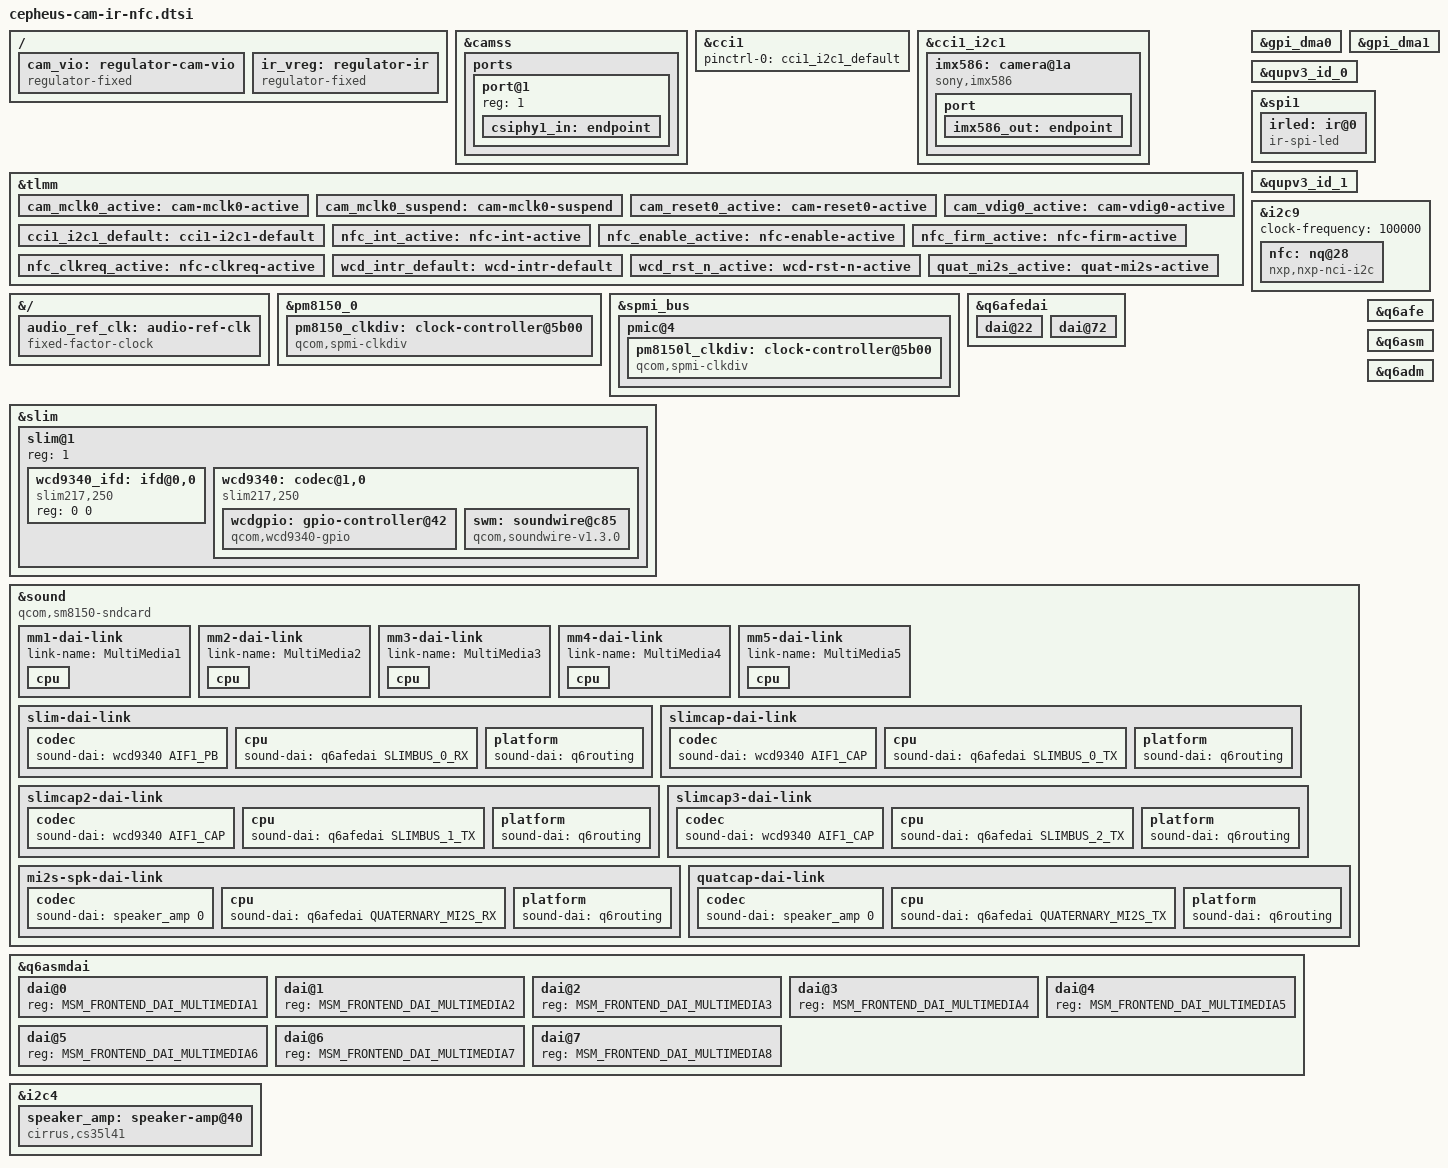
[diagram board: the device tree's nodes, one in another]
// SPDX-License-Identifier: GPL-2.0
#include <dt-bindings/sound/qcom,q6afe.h>
#include <dt-bindings/sound/qcom,q6asm.h>
#include <dt-bindings/sound/qcom,wcd934x.h>
/*
 * Xiaomi Mi 9 (cepheus) 鈥旓拷?鐩告満 / 绾㈠ / NFC 鐨勬澘绾цˉ锟? *
 * 锟?scripts/apply-dts5.sh 杩藉姞锟?sm8150-xiaomi-cepheus.dts 鏈熬锟? * 杩欐牱 07-rebuild-all 涔嬬被鐨勫畬鏁撮噸寤轰笉浼氭妸瀹冨啿鎺夛拷? *
 * 鐩告満閮ㄥ垎鐩墠鐘舵€侊細SoC 渚у叏閮ㄦ墦閫氾紙鏃堕挓/GDSC/CCI/camss锛夛紝
 * 浣嗘ā缁勬湰韬笉涓婄數锛岃锟?docs/camera-port.md 搂15锟? */

/ {
	/* 鐩告満 VIO锟?.8V锛孏PIO132 浣胯兘锛堝師锟?camera_viodd_ldo锟?*/
	cam_vio: regulator-cam-vio {
		compatible = "regulator-fixed";
		regulator-name = "cam_vio";
		regulator-min-microvolt = <1800000>;
		regulator-max-microvolt = <1800000>;
		regulator-enable-ramp-delay = <135>;
		enable-active-high;
		gpio = <&tlmm 132 GPIO_ACTIVE_HIGH>;
		regulator-always-on;
	};

	/* 绾㈠鍙戝皠绠＄殑渚涚數锛坕r-spi 椹卞姩瑕佹眰鍚嶄负 irda_regulator 鐨勭數婧愶級 */
	ir_vreg: regulator-ir {
		compatible = "regulator-fixed";
		regulator-name = "ir_vreg";
		regulator-min-microvolt = <3300000>;
		regulator-max-microvolt = <3300000>;
		regulator-always-on;
	};
};

/* ================= 鐩告満 ================= */

&camss {
	status = "okay";

	ports {
		#address-cells = <1>;
		#size-cells = <0>;

		port@1 {
			reg = <1>;

			csiphy1_in: endpoint {
				remote-endpoint = <&imx586_out>;
				bus-type = <4>;
				data-lanes = <1 2 3 4>;
				link-frequencies = /bits/ 64 <400000000>;
			};
		};
	};
};

&cci1 {
	status = "okay";
	pinctrl-names = "default";
	pinctrl-0 = <&cci1_i2c1_default>;
};

&cci1_i2c1 {
	status = "okay";

	imx586: camera@1a {
		compatible = "sony,imx586";
		reg = <0x1a>;

		reset-gpios = <&tlmm 30 GPIO_ACTIVE_HIGH>;
		pwdn-gpios = <&tlmm 59 GPIO_ACTIVE_HIGH>;

		clocks = <&camcc CAM_CC_MCLK1_CLK>;
		clock-names = "xvclk";

		pinctrl-names = "default", "suspend";
		pinctrl-0 = <&cam_mclk0_active &cam_reset0_active &cam_vdig0_active>;
		pinctrl-1 = <&cam_mclk0_suspend>;

		/* IMX586锛欰VDD 2.8V銆丏OVDD 1.8V銆丏VDD 1.1锟?.9V
		 * 鍘熷巶 DT 鍛藉悕鏄弽鐨勶紙cam_vdig 2.856V 鎵嶆槸 AVDD锟?		 */
		avdd-supply = <&vreg_l17a_3p0>;
		dovdd-supply = <&cam_vio>;
		dvdd-supply = <&vreg_s5a_1p9>;

		port {
			imx586_out: endpoint {
				remote-endpoint = <&csiphy1_in>;
				bus-type = <4>;
				data-lanes = <1 2 3 4>;
				link-frequencies = /bits/ 64 <400000000>;
			};
		};
	};
};

&tlmm {
	cam_mclk0_active: cam-mclk0-active {
		pins = "gpio14";
		function = "cam_mclk";
		drive-strength = <2>;
		bias-disable;
	};

	cam_mclk0_suspend: cam-mclk0-suspend {
		pins = "gpio14";
		function = "cam_mclk";
		drive-strength = <2>;
		bias-pull-down;
	};

	cam_reset0_active: cam-reset0-active {
		pins = "gpio30";
		function = "gpio";
		drive-strength = <2>;
		bias-disable;
	};

	cam_vdig0_active: cam-vdig0-active {
		pins = "gpio59";
		function = "gpio";
		drive-strength = <2>;
		bias-disable;
	};

	cci1_i2c1_default: cci1-i2c1-default {
		pins = "gpio31", "gpio32", "gpio33", "gpio34";
		function = "cci_i2c";
		drive-strength = <2>;
		bias-disable;
	};
};

/* ================= 绾㈠锛圫PI1 / QUP S1, gpio114-117锟?================= */

/* QUP 锟?GPI DMA锛坓eni-i2c/spi 闇€瑕侊級 */
&gpi_dma0 {
	status = "okay";
};

&gpi_dma1 {
	status = "okay";
};

/* IR 锟?qupv3_id_0锛坓eniqup@8c0000锛変笅锟?spi1 */
&qupv3_id_0 {
	status = "okay";
};

&spi1 {
	status = "okay";

	irled: ir@0 {
		compatible = "ir-spi-led";
		reg = <0>;
		spi-max-frequency = <19200000>;
		irda_regulator-supply = <&ir_vreg>;
	};
};

/* ================= NFC锛圢XP NQ, i2c9, 鍦板潃 0x28锟?================= */

&tlmm {
	nfc_int_active: nfc-int-active {
		pins = "gpio47";
		function = "gpio";
		drive-strength = <2>;
		bias-pull-up;
	};

	nfc_enable_active: nfc-enable-active {
		pins = "gpio103";
		function = "gpio";
		drive-strength = <2>;
		bias-disable;
	};

	nfc_firm_active: nfc-firm-active {
		pins = "gpio48";
		function = "gpio";
		drive-strength = <2>;
		bias-disable;
	};

	/* 原锟斤拷锟斤拷 NFC 锟斤拷 CLKREQ 锟脚ｏ拷GPIO113锟斤拷锟斤拷纱锟斤拷锟斤拷锟斤拷锟斤拷锟斤拷耄?	 * 锟斤拷锟斤拷幕锟斤拷锟斤拷锟斤拷锟斤拷锟秸ｏ拷芯片锟矫诧拷锟斤拷锟轿匡拷时锟接ｏ拷I2C 锟斤拷直锟斤拷锟斤拷应锟斤拷-121锟斤拷锟斤拷
	 */
	nfc_clkreq_active: nfc-clkreq-active {
		pins = "gpio113";
		function = "gpio";
		drive-strength = <2>;
		bias-pull-up;
	};};

/* NFC 锟?qupv3_id_1锛坓eniqup@ac0000锛変笅锟?i2c9 */
&qupv3_id_1 {
	status = "okay";
};

/* RPMH 鐨?LN_BB_CLK2 鍥哄畾 19.2MHz锛岃€?WCD9340 闇€瑕?9.6MHz銆? * 鍘熷巶鐢?qcom,audio-ref-clk 椹卞姩浜屽垎棰戯紝涓荤嚎娌¤繖涓┍鍔紝
 * 鎴戜滑涓€鐩存妸 19.2MHz 鐩存帴缁?codec銆侀┍鍔ㄥ嵈鎸?9.6MHz 绠楀垎棰戯紝
 * 鏃堕挓宸?2 鍊?鈥斺€?杩欐槸 ADC/DEC 鏃犳硶宸ヤ綔鐨勭洿鎺ュ師鍥犮€? * 鐢ㄦ爣鍑?fixed-factor-clock 瀹炵幇浜屽垎棰戙€? */
&{/} {
	audio_ref_clk: audio-ref-clk {
		compatible = "fixed-factor-clock";
		clocks = <&rpmhcc RPMH_LN_BB_CLK2>;
		#clock-cells = <0>;
		clock-div = <2>;
		clock-mult = <1>;
		clock-output-names = "audio_ref_clk";
	};
};

/* 鈽?PM8150 鐨勬椂閽熷垎棰戝櫒锛坰pmi-clkdiv锛夈€? * NFC 鐨勫弬鑰冩椂閽熷氨鏉ヨ嚜杩欓噷 鈥斺€?鑺墖鎷変綆 CLKREQ 璇锋眰鏃堕挓锛? * 鐢?PMIC 鐨?div_clk 杈撳嚭缁欏畠锛圕LKREQ 闂ㄦ帶鏄‖浠惰涓猴級銆? * 涓荤嚎 pm8150.dtsi 閲屾牴鏈病鏈夎繖涓妭鐐癸紝鎵€浠ヨ繖浜涙椂閽熶粠涓嶈緭鍑猴紝
 * 鑺墖鎷夸笉鍒版椂閽?鈫?I2C 鑳?ACK 浣嗚鍥炲叏鏄?0銆? */
&pm8150_0 {
	pm8150_clkdiv: clock-controller@5b00 {
		compatible = "qcom,spmi-clkdiv";
		reg = <0x5b00 0x200>;
		#clock-cells = <1>;
		qcom,num-clkdivs = <2>;
		clock-output-names = "pm8150_div_clk1", "pm8150_div_clk2";
		clocks = <&rpmhcc RPMH_CXO_CLK>;
		clock-names = "xo";
	};
};

/* PM8150L 鐨勫垎棰戞椂閽燂紙鍙兘鏄?NFC 鐨勬椂閽熸簮锛?*/
&spmi_bus {
	pmic@4 {
		pm8150l_clkdiv: clock-controller@5b00 {
			compatible = "qcom,spmi-clkdiv";
			reg = <0x5b00 0x100>;
			#clock-cells = <1>;
			qcom,num-clkdivs = <1>;
			clock-output-names = "pm8150l_div_clk1";
			clocks = <&rpmhcc RPMH_CXO_CLK>;
			clock-names = "xo";
		};
	};
};

&i2c9 {
	status = "okay";
	/* SN100U 锟较碉拷锟斤拷锟斤拷锟斤拷锟?100kHz锟斤拷锟脚筹拷锟斤拷锟斤拷锟绞碉拷锟铰的诧拷锟斤拷应 */
	clock-frequency = <100000>;

	nfc: nq@28 {
		compatible = "nxp,nxp-nci-i2c";
		reg = <0x28>;

		interrupt-parent = <&tlmm>;
		/* NXP NQ 锟?IRQ 蹇呴』鐢ㄨ竟娌胯Е鍙戯細鑺墖鏁版嵁娌¤璇昏蛋鏃朵細鎶婄嚎涓€鐩存媺楂橈紝
	 * 鐢ㄧ數骞宠Е鍙戜細閫犳垚涓柇椋庢毚鎶婄郴缁熷崱姝伙拷?*/
		interrupts = <47 IRQ_TYPE_EDGE_RISING>;
		interrupt-names = "nfc_irq";

		enable-gpios = <&tlmm 103 GPIO_ACTIVE_HIGH>;
		firmware-gpios = <&tlmm 48 GPIO_ACTIVE_HIGH>;

		/* SN100U 锟侥参匡拷时锟斤拷锟斤拷锟斤拷 PMIC 锟斤拷 ln_bb_clk3锟斤拷19.2MHz锟斤拷锟斤拷
		 * CLKREQ 一直锟斤拷锟酵憋拷示锟斤拷锟斤拷锟斤拷时锟接ｏ拷没时锟斤拷芯片锟斤拷锟斤拷全锟斤拷锟斤拷应 NCI锟斤拷
		 */
		clocks = <&pm8150_clkdiv 1>, <&pm8150_clkdiv 2>, <&pm8150l_clkdiv 1>;
		clock-names = "nfc_clk", "nfc_clk2", "nfc_clk3";

		pinctrl-names = "default";
		pinctrl-0 = <&nfc_int_active &nfc_enable_active &nfc_firm_active &nfc_clkreq_active>;
	};
};

/* ================= 闊抽锛歐CD9340锛堝師锟?tavil锟?================= */
/* 鍘熷巶鎺ョ嚎锛歝odec IRQ=GPIO123锛屽锟?GPIO143锛堜綆鏈夋晥澶嶄綅锛岄┍鍔ㄨ嚜宸辨帶鍒讹級
 * 鐢垫簮锛歷dd-buck/tx/rx/io = pm8150 S4锟?.8V锛夛紝vdd-vbat/3v3 = BOB
 */

&tlmm {
	wcd_intr_default: wcd-intr-default {
		pins = "gpio123";
		function = "gpio";
		drive-strength = <2>;
		bias-pull-up;
	};

	wcd_rst_n_active: wcd-rst-n-active {
		pins = "gpio143";
		function = "gpio";
		drive-strength = <2>;
		bias-disable;
	};
};

&slim {
	status = "okay";

	slim@1 {
		reg = <1>;
		#address-cells = <2>;
		#size-cells = <0>;

		wcd9340_ifd: ifd@0,0 {
			compatible = "slim217,250";
			reg = <0 0>;
		};

		wcd9340: codec@1,0 {
			compatible = "slim217,250";
			reg = <1 0>;
			slim-ifc-dev = <&wcd9340_ifd>;

			#sound-dai-cells = <1>;

			interrupts-extended = <&tlmm 123 IRQ_TYPE_LEVEL_HIGH>;
			interrupt-controller;
			#interrupt-cells = <1>;

			reset-gpios = <&tlmm 143 GPIO_ACTIVE_HIGH>;

			clock-names = "extclk";
			clocks = <&audio_ref_clk>;
			#clock-cells = <0>;
			clock-frequency = <9600000>;
			clock-output-names = "mclk";

			pinctrl-names = "default";
			pinctrl-0 = <&wcd_intr_default &wcd_rst_n_active>;

			vdd-buck-supply = <&vreg_s4a_1p8>;
			vdd-buck-sido-supply = <&vreg_s4a_1p8>;
			vdd-tx-supply = <&vreg_s4a_1p8>;
			vdd-rx-supply = <&vreg_s4a_1p8>;
			vdd-io-supply = <&vreg_s4a_1p8>;
			vdd-micbias-supply = <&vreg_s4a_1p8>;
			vdd-vbat-supply = <&vreg_bob>;

			qcom,micbias1-microvolt = <1800000>;
			qcom,micbias2-microvolt = <1800000>;
			qcom,micbias3-microvolt = <1800000>;
			qcom,micbias4-microvolt = <1800000>;

			#address-cells = <1>;
			#size-cells = <1>;

			wcdgpio: gpio-controller@42 {
				compatible = "qcom,wcd9340-gpio";
				gpio-controller;
				#gpio-cells = <2>;
				reg = <0x42 0x2>;
			};

			swm: soundwire@c85 {
				compatible = "qcom,soundwire-v1.3.0";
				reg = <0xc85 0x40>;
				interrupts-extended = <&wcd9340 20>;

				qcom,dout-ports = <6>;
				qcom,din-ports = <2>;
				qcom,ports-sinterval-low = /bits/ 8 <0x07 0x1f 0x3f 0x07 0x1f 0x3f 0x0f 0x0f>;
				qcom,ports-offset1 = /bits/ 8 <0x01 0x02 0x0c 0x06 0x12 0x0d 0x07 0x0a>;
				qcom,ports-offset2 = /bits/ 8 <0x00 0x00 0x1f 0x00 0x00 0x1f 0x00 0x00>;

				#sound-dai-cells = <1>;
				clocks = <&wcd9340>;
				clock-names = "iface";
				#address-cells = <2>;
				#size-cells = <0>;
			};
		};
	};
};

/* ================= 澹板崱 ================= */


/* secondary MI2S 锟?SD 绾匡細鍘熷巶涓よ矾 SD0(GPIO128)/SD1(GPIO129)锟? * 娌℃湁杩欎釜灞烇拷?q6afe 锟?sd_line_mask 灏辨槸 0锛宲repare 锟?-22锟? */
&q6afedai {
	dai@22 {
		reg = <QUATERNARY_MI2S_RX>;
		qcom,sd-lines = <0>;
	};
};

&sound {
	compatible = "qcom,sm8150-sndcard";
	model = "sm8150-tavil-snd-card";
	status = "okay";

	audio-routing =
		"RX_BIAS", "MCLK",
		"AMIC1", "MCLK",
		"AMIC3", "MCLK",
		"AMIC4", "MCLK",
		"DMIC1", "MCLK",
		"DMIC3", "MCLK",
		"DMIC4", "MCLK",
		"DMIC5", "MCLK",
		"AMIC1", "MIC BIAS1",
		"AMIC2", "MIC BIAS2",
		"AMIC3", "MIC BIAS3",
		"AMIC4", "MIC BIAS4",
		"DMIC0", "MCLK",
		"DMIC0", "MIC BIAS1",
		"DMIC2", "MCLK",
		"DMIC2", "MIC BIAS3",
		"DMIC3", "MIC BIAS3",
		"DMIC4", "MIC BIAS4",
		"DMIC5", "MIC BIAS4";

	mm1-dai-link {
		link-name = "MultiMedia1";
		cpu { sound-dai = <&q6asmdai MSM_FRONTEND_DAI_MULTIMEDIA1>; };
	};
	mm2-dai-link {
		link-name = "MultiMedia2";
		cpu { sound-dai = <&q6asmdai MSM_FRONTEND_DAI_MULTIMEDIA2>; };
	};
	mm3-dai-link {
		link-name = "MultiMedia3";
		cpu { sound-dai = <&q6asmdai MSM_FRONTEND_DAI_MULTIMEDIA3>; };
	};
	mm4-dai-link {
		link-name = "MultiMedia4";
		cpu { sound-dai = <&q6asmdai MSM_FRONTEND_DAI_MULTIMEDIA4>; };
	};
	mm5-dai-link {
		link-name = "MultiMedia5";
		cpu { sound-dai = <&q6asmdai MSM_FRONTEND_DAI_MULTIMEDIA5>; };
	};

	slim-dai-link {
		link-name = "SLIM Playback 1";
		no-pcm;
		codec { sound-dai = <&wcd9340 AIF1_PB>; };
		cpu { sound-dai = <&q6afedai SLIMBUS_0_RX>; };
		platform { sound-dai = <&q6routing>; };
	};

	slimcap-dai-link {
		link-name = "SLIM Capture 1";
		no-pcm;
		codec { sound-dai = <&wcd9340 AIF1_CAP>; };
		cpu { sound-dai = <&q6afedai SLIMBUS_0_TX>; };
		platform { sound-dai = <&q6routing>; };
	};

	/* 锟?閲囬泦绔彛鎺掓煡鐢細鎶婂彟澶栧嚑锟?SLIM TX 绔彛涔熸寕涓婂悓涓€锟?codec 閲囬泦 DAI锟?	 * 鐢ㄦ潵纭楹﹀厠椋庡埌搴曡蛋鐨勬槸鍝釜 AFE SLIM 绔彛锟?026-10-21锛夛拷?	 */
	slimcap2-dai-link {
		link-name = "SLIM Capture 2";
		no-pcm;
		codec { sound-dai = <&wcd9340 AIF1_CAP>; };
		cpu { sound-dai = <&q6afedai SLIMBUS_1_TX>; };
		platform { sound-dai = <&q6routing>; };
	};

	slimcap3-dai-link {
		link-name = "SLIM Capture 3";
		no-pcm;
		codec { sound-dai = <&wcd9340 AIF1_CAP>; };
		cpu { sound-dai = <&q6afedai SLIMBUS_2_TX>; };
		platform { sound-dai = <&q6routing>; };
	};

	/* 鎵０鍣細AFE secondary MI2S -> CS35L41 -> 鍠囧彮 */
	mi2s-spk-dai-link {
		link-name = "SEC MI2S Playback";
		no-pcm;

		codec { sound-dai = <&speaker_amp 0>; };
		cpu { sound-dai = <&q6afedai QUATERNARY_MI2S_RX>; };
		platform { sound-dai = <&q6routing>; };
	};

	/* 鐜洖鑷鐢細鍔熸斁鐨?ASP TX 浼氭妸 ASPRX 鏀跺埌鐨勬暟鎹洖鏄惧嚭鏉ワ紝
	 * 鐢ㄨ繖鏉￠摼璺粠 QUAT MI2S TX 閲囧洖鏉ワ紝灏辫兘鍦ㄤ笉鎺ョず娉㈠櫒鐨?	 * 鎯呭喌涓嬬‘璁?I2S 鏁版嵁鍒板簳鏈夋病鏈夐€佸埌鍔熸斁銆?	 */
	quatcap-dai-link {
		link-name = "QUAT MI2S Capture";
		no-pcm;

		codec { sound-dai = <&speaker_amp 0>; };
		cpu { sound-dai = <&q6afedai QUATERNARY_MI2S_TX>; };
		platform { sound-dai = <&q6routing>; };
	};

};

/* q6asm-dai 闇€瑕佸瓙鑺傜偣锛屽惁鍒欐姤 "No dais found in DT" */
&q6asmdai {
	dai@0 { reg = <MSM_FRONTEND_DAI_MULTIMEDIA1>; };
	dai@1 { reg = <MSM_FRONTEND_DAI_MULTIMEDIA2>; };
	dai@2 { reg = <MSM_FRONTEND_DAI_MULTIMEDIA3>; };
	dai@3 { reg = <MSM_FRONTEND_DAI_MULTIMEDIA4>; };
	dai@4 { reg = <MSM_FRONTEND_DAI_MULTIMEDIA5>; };
	dai@5 { reg = <MSM_FRONTEND_DAI_MULTIMEDIA6>; };
	dai@6 { reg = <MSM_FRONTEND_DAI_MULTIMEDIA7>; };
	dai@7 { reg = <MSM_FRONTEND_DAI_MULTIMEDIA8>; };
};

/* apr 闊抽鏈嶅姟闇€瑕佹寕锟?ADSP 锟?audio protection domain锟? * 鍚﹀垯 q6asm 锟?buffer memory-map 浼氳 DSP 鎷掔粷锛坋rror 1锛夛拷? * sdm845/sm8250 鐨勪富锟?DT 閮芥湁杩欎釜灞炴€э紝sm8150 锟?dtsi 婕忎簡锟? */
&q6afe {
	qcom,protection-domain = "avs/audio", "msm/adsp/audio_pd";
};

&q6asm {
	qcom,protection-domain = "avs/audio", "msm/adsp/audio_pd";
};

&q6adm {
	qcom,protection-domain = "avs/audio", "msm/adsp/audio_pd";
};

/* ================= 鎵０鍣ㄥ姛鏀撅細Cirrus CS35L41 =================
 * 鍘熷巶 DT锛歩2c@890000锛堜富锟?i2c4锛夊湴鍧€ 0x40锛屽锟?GPIO89锛堜綆鏈夋晥锛夛紝
 * 涓柇 GPIO10锛堜綆鐢靛钩锛夈€備富绾挎湁 cs35l41 椹卞姩涓斿凡缂栨垚妯″潡锟? * 娉ㄦ剰锛氬彧寮€杩欎竴鏉℃€荤嚎 鈥旓拷?涔嬪墠涓€娆℃€ф墦寮€鎵€锟?QUP 鎬荤嚎瀵艰嚧鏃犳硶寮€鏈猴拷? */
&i2c4 {
	status = "okay";

	speaker_amp: speaker-amp@40 {
		compatible = "cirrus,cs35l41";
		reg = <0x40>;
		#sound-dai-cells = <1>;

		/* 涓荤嚎 cs35l41 椹卞姩鍋囪澶嶄綅鏄珮鏈夋晥锛氬厛鎷変綆 2ms 鍐嶆媺楂橀噴鏀撅拷?		 * 鍘熸潵鎸夊師鍘傝涔夊啓锟?ACTIVE_LOW锛岄€昏緫 1 鍙嶈€屽彉鎴愮墿鐞嗕綆锟?		 * 绛変簬涓€鐩存寜鐫€澶嶄綅锛岃姱鐗囨案杩滅瓑涓嶅埌 OTP_BOOT_DONE锟?		 */
		VA-supply = <&vreg_s4a_1p8>;
		VP-supply = <&vreg_bob>;

		/* 鈽?涓嶈缁?MI2S 寮曡剼閰?pinctrl锛欸PIO126-129锛坰econdary MI2S锛?		 * 鏄?bootloader/TrustZone 淇濈暀鐨勶紙鍏朵粬 sm8150 鏉垮瓙 DT 閮藉啓鐫€
		 * gpio-reserved-ranges = <126 4>锛夛紝Linux 涓€ request 灏?-EINVAL锛?		 * 瀵艰嚧鍔熸斁 probe 澶辫触銆佸０鍗℃敞鍐屼笉鍑烘潵銆傝繖浜涘紩鑴氬凡鐢?ABL 澶嶇敤濂姐€?		 */
		pinctrl-names = "default";
		pinctrl-0 = <&quat_mi2s_active>;

		reset-gpios = <&tlmm 89 GPIO_ACTIVE_HIGH>;
		interrupt-parent = <&tlmm>;
		interrupts = <10 IRQ_TYPE_LEVEL_LOW>;

		cirrus,boost-peak-milliamp = <4000>;
		cirrus,boost-ind-nanohenry = <1000>;
		cirrus,boost-cap-microfarad = <15>;
		/* 鍘熷巶锟?cirrus,gpio-config2: gpio-src-select=4 + output-enable */
		cirrus,gpio2-src-select = <4>;
		cirrus,gpio2-output-enable;
	};
};

/* 鎵０鍣ㄥ姛鏀剧殑闊抽杈撳叆锛歴econdary MI2S锛堝師锟?gpio126-129锟?*/
&tlmm {
	/* 鎵０鍣ㄨ蛋鐨勬槸 secondary MI2S锛圙PIO126-130锛夛紝涓嶆槸 quaternary銆?	 * 涔嬪墠鐢?qua_mi2s 鐨勫紩鑴氾紙136-140锛夛紝缁撴灉鍔熸斁鎷夸笉鍒颁綅鏃堕挓銆丳LL 閿佷笉涓娿€?	 * 涓婄數瓒呮椂 -110銆?	 */
	/* 鎵０鍣ㄥ姛鏀剧殑 I2S = QUATERNARY MI2S锛坓pio136 SCLK / 137 WS / 138-140 SD锛夈€?	 * 璇佹嵁锛氱敤 QUATERNARY 鏃跺姛鏀剧殑 PLL 鑳介攣瀹氾紙PLL_LOCK=1锛夛紝
	 * 鑰?secondary MI2S 鐨?gpio126-129 寮€鏈哄悗鏄?MUX UNCLAIMED锛?	 * 涓斾竴澶嶇敤灏辨鏈猴紙TZ 淇濇姢锛夆€斺€?閭ｅ嚑鏍圭嚎涓嶆槸闊抽鐢ㄧ殑銆?	 */
	quat_mi2s_active: quat-mi2s-active {
		pins = "gpio136", "gpio137", "gpio138", "gpio139", "gpio140", "gpio141", "gpio142";
		function = "qua_mi2s";
		drive-strength = <8>;
		bias-disable;
	};
};

/* ==========================================================================
 * 2026-10-22 鎵０鍣ㄤ慨澶嶈ˉ涓侊紙渚濇嵁涓荤嚎宸插悎鍏ヤ笖鐪熸満鍙敤鐨?sm8150-xiaomi-nabu.dts锛? *
 * 1) QUAT TDM 鐨?6 涓抚鍙傛暟鍏ㄩ儴缂哄け -> q6afe 閲?of_property_read_u32 鍏ㄥけ璐ワ紝
 *    sync_mode/sync_src/data_out/invert_sync/data_delay/data_align 鍏ㄤ负 0銆? *    瀹炴祴锛欰FE 绔彛鑳借捣銆丼CLK 12.288MHz銆佸姛鏀?PLL 閿併€佸瘎瀛樺櫒鍏ㄥ锛? *          浣嗗姛鏀句竴涓湁鏁堟暟鎹兘鏀朵笉鍒帮紙妲戒綅 0~7 + 鎵€鏈夋瀬鎬?甯ф牸寮忕粍鍚堝叏闈欓煶锛夈€? *    nabu 涓婃槸 1/1/0/1/1/0锛岃繖閲岀収鎶勩€? *
 * 2) cirrus,asp-sdout-hiz 缂哄け锛歯abu 璁?<3>锛屼富绾块粯璁ゅ啓 0x02銆? * ========================================================================== */
&q6afedai {
	dai@72 {
		reg = <QUATERNARY_TDM_RX_0>;
		qcom,tdm-sync-mode = <1>;
		qcom,tdm-sync-src = <1>;
		qcom,tdm-data-out = <0>;
		qcom,tdm-invert-sync = <1>;
		qcom,tdm-data-delay = <1>;
		qcom,tdm-data-align = <0>;
	};
};

&speaker_amp {
	cirrus,asp-sdout-hiz = <3>;
};
